AUTOSAR XML (schema 4-2-2)
package /Components
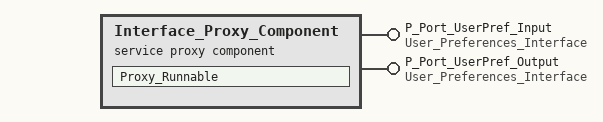
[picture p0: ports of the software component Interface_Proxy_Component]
  service proxy sw component type Interface_Proxy_Component
    provide port P_Port_UserPref_Input: provided-interface=User_Preferences_Interface
    provide port P_Port_UserPref_Output: provided-interface=User_Preferences_Interface
    behavior Interface_Proxy_Component_Behavior: handle-termination-and-restart=true
      init event Init_E: start-on-event=Proxy_Runnable
      runnable Proxy_Runnable: minimum-start-interval=10, symbol=Proxy_Runnable_Sym
        data-receive-point-by-values:
          access UI_PREF_Read_Brightness: accessed-variable=P_Port_UserPref_Input.BRIGHTNESS_PRESET
          access UI_PREF_Read_Mode: accessed-variable=P_Port_UserPref_Input.PREFERRED_MODE
        data-send-points:
          access BRIGHTNESS_PRESET_Send: accessed-variable=P_Port_UserPref_Output.BRIGHTNESS_PRESET
          access PREF_MODE_Send: accessed-variable=P_Port_UserPref_Output.PREFERRED_MODE
